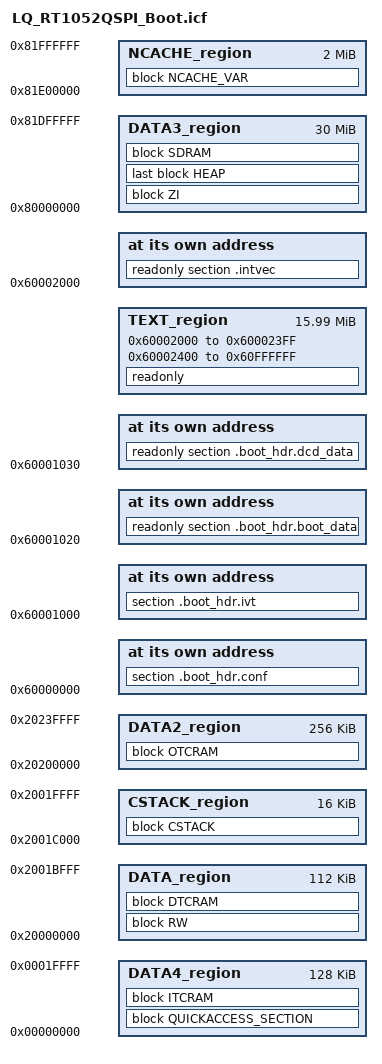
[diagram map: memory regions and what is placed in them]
/*LLLLLLLLLLLLLLLLLLLLLLLLLLLLLLLLLLLLLLLLLLLLLLLLLLLLLLLLLLLLLL
【平    台】龙邱i.MX RT1052核心板-智能车板
【编    写】CHIUSIR
【E-mail  】chiusir@163.com
【软件版本】V1.0，龙邱开源代码，仅供参考，后果自负
【最后更新】2018年2月5日
【相关信息参考下列地址】
【网    站】http://www.lqist.cn
【淘宝店铺】http://shop36265907.taobao.com
------------------------------------------------
【dev.env.】IAR8.20.1及以上版本
【Target 】 i.MX RT1052
【Crystal】 24.000Mhz
【ARM PLL】 1200MHz
【SYS PLL】 528MHz
【USB PLL】 480MHz
================================================
北京龙邱智能科技：从 16MB QSPI FLASH启动，SDRAM为32MB字节
QQQQQQQQQQQQQQQQQQQQQQQQQQQQQQQQQQQQQQQQQQQQQQQQQQQQQQQQQQQQQQQ*/
define exported symbol m_boot_hdr_conf_start = 0x60000000;
define symbol m_boot_hdr_ivt_start           = 0x60001000;
define symbol m_boot_hdr_boot_data_start     = 0x60001020;
define symbol m_boot_hdr_dcd_data_start      = 0x60001030;

define symbol m_interrupts_start       = 0x60002000;
define symbol m_interrupts_end         = 0x600023FF;


define symbol m_text_start             = 0x60002400;
define symbol m_text_end               = 0x60FFFFFF;

//ITCRAM
define symbol ITCRAM_start             = 0x00000000;
define symbol ITCRAM_end               = 0x0001FFFF;

//DTCRAM
define symbol m_data_start             = 0x20000000;
define symbol m_data_end               = 0x2001FFFF;

//OTCRAM
define symbol m_data2_start            = 0x20200000;
define symbol m_data2_end              = 0x2023FFFF;

//SDRAM
define symbol m_data3_start            = 0x80000000;
define symbol m_data3_end              = 0x81DFFFFF;

//分配2M NCACHE_VAR
define symbol m_ncache_start           = 0x81E00000;
define symbol m_ncache_end             = 0x81FFFFFF;

/* Sizes */
if (isdefinedsymbol(__stack_size__)) {
  define symbol __size_cstack__        = __stack_size__;
} else {
  define symbol __size_cstack__        = 0x4000;
}

if (isdefinedsymbol(__heap_size__)) {
  define symbol __size_heap__          = __heap_size__;
} else {
  define symbol __size_heap__          = 0x8000;
}

define exported symbol __VECTOR_TABLE  = m_interrupts_start;
define exported symbol __VECTOR_RAM    = m_interrupts_start;
define exported symbol __RAM_VECTOR_TABLE_SIZE = 0x0;

define memory mem with size = 4G;
define region TEXT_region = mem:[from m_interrupts_start to m_interrupts_end]
                          | mem:[from m_text_start to m_text_end];

define region DATA_region = mem:[from m_data_start to m_data_end-__size_cstack__];
define region DATA2_region = mem:[from m_data2_start to m_data2_end];
define region DATA3_region  = mem:[from m_data3_start to m_data3_end];
define region DATA4_region  = mem:[from ITCRAM_start to ITCRAM_end];
define region CSTACK_region = mem:[from m_data_end-__size_cstack__+1 to m_data_end];
define region NCACHE_region = mem:[from m_ncache_start to m_ncache_end];

define block CSTACK    with alignment = 8, size = __size_cstack__   { };
define block HEAP      with alignment = 8, size = __size_heap__     { };
define block RW        { first readwrite, section m_usb_dma_init_data };
define block ZI         with alignment = 32  { first zi, section m_usb_dma_noninit_data };
define block NCACHE_VAR with size = 0x200000 , alignment = 0x100000  { section NonCacheable , section NonCacheable.init };
define block QUICKACCESS_SECTION  { section CodeQuickAccess , section DataQuickAccess };


define block ITCRAM  { section ITCRAMAccess};
define block DTCRAM  { section DTCRAMAccess};
define block OTCRAM  { section OTCRAMAccess};
define block SDRAM   { section SDRAMAccess};

initialize by copy { readwrite, section .textrw, section SDRAMAccess, section ITCRAMAccess, section DTCRAMAccess, section OTCRAMAccess, section CodeQuickAccess, section DataQuickAccess};
do not initialize  { section .noinit };

place at address mem: m_interrupts_start    { readonly section .intvec };

place at address mem:m_boot_hdr_conf_start { section .boot_hdr.conf };
place at address mem:m_boot_hdr_ivt_start { section .boot_hdr.ivt };
place at address mem:m_boot_hdr_boot_data_start { readonly section .boot_hdr.boot_data };
place at address mem:m_boot_hdr_dcd_data_start { readonly section .boot_hdr.dcd_data };


keep{ section .boot_hdr.conf, section .boot_hdr.ivt, section .boot_hdr.boot_data, section .boot_hdr.dcd_data };

//程序和const变量 储存位置
place in TEXT_region                        { readonly };

//已初始化全局变量和static变量（非零） 存放区域
place in DATA_region                        { block RW };

//未初始化全局变量和static变量或初始化为零的 存放区域
place in DATA3_region                       { block ZI };

//堆区域 malloc申请内存时使用
place in DATA3_region                       { last block HEAP };

//栈区域 
place in CSTACK_region                      { block CSTACK };

//NCACHE 区域
place in NCACHE_region                      { block NCACHE_VAR };

place in DATA4_region                       { block QUICKACCESS_SECTION };

place in DATA4_region                       { block ITCRAM };
place in DATA_region                        { block DTCRAM };
place in DATA2_region                       { block OTCRAM };
place in DATA3_region                       { block SDRAM };
